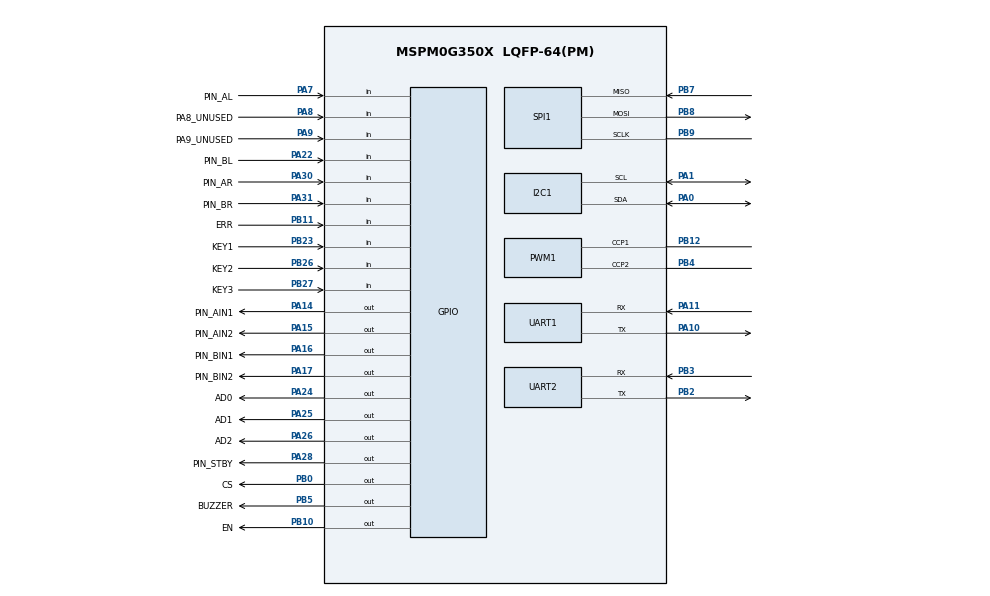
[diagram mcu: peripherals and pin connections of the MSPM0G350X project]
/**
 *
 * @cliArgs --device "MSPM0G350X" --part "Default" --package "LQFP-64(PM)" --product "mspm0_sdk@2.09.00.01"
 * @versions {"tool":"1.28.0+4696"}
 */

/**
 * Import the modules used in this configuration.
 */
const ADC12         = scripting.addModule("/ti/driverlib/ADC12", {}, false);
const ADC121        = ADC12.addInstance();
const GPIO          = scripting.addModule("/ti/driverlib/GPIO", {}, false);
const GPIO1         = GPIO.addInstance();
const GPIO2         = GPIO.addInstance();
const GPIO3         = GPIO.addInstance();
const GPIO4         = GPIO.addInstance();
const GPIO5         = GPIO.addInstance();
const GPIO6         = GPIO.addInstance();
const GPIO7         = GPIO.addInstance();
const GPIO8         = GPIO.addInstance();
const GPIO9         = GPIO.addInstance();
const GPIO10        = GPIO.addInstance();
const I2C           = scripting.addModule("/ti/driverlib/I2C", {}, false);
const I2C1          = I2C.addInstance();
const PWM           = scripting.addModule("/ti/driverlib/PWM", {}, false);
const PWM1          = PWM.addInstance();
const SPI           = scripting.addModule("/ti/driverlib/SPI", {}, false);
const SPI1          = SPI.addInstance();
const SYSCTL        = scripting.addModule("/ti/driverlib/SYSCTL");
const UART          = scripting.addModule("/ti/driverlib/UART", {}, false);
const UART1         = UART.addInstance();
const UART2         = UART.addInstance();
const WWDT          = scripting.addModule("/ti/driverlib/WWDT", {}, false);
const WWDT1         = WWDT.addInstance();
const ProjectConfig = scripting.addModule("/ti/project_config/ProjectConfig");

/**
 * Write custom configuration values to the imported modules.
 */
/* ADC0 serves the GRAY multiplexer output only. */
ADC121.$name                             = "ADC_GRAY";
ADC121.sampleTime0                       = "40 us";
ADC121.sampClkDiv                        = "DL_ADC12_CLOCK_DIVIDE_8";
ADC121.samplingOperationMode              = "sequence";
ADC121.endAdd                             = 0;
ADC121.enabledInterrupts                 = ["DL_ADC12_INTERRUPT_MEM0_RESULT_LOADED"];
ADC121.adcMem0_name                      = "GRAY_OUT";
ADC121.adcMem0chansel                    = "DL_ADC12_INPUT_CHAN_0";
ADC121.peripheral.$assign                = "ADC0";
ADC121.peripheral.adcPin0.$assign        = "PA27";
ADC121.adcPin0Config.hideOutputInversion = scripting.forceWrite(false);
ADC121.adcPin0Config.$name               = "GPIO_ADC_GRAY_OUT";

const Board = scripting.addModule("/ti/driverlib/Board", {}, false);

GPIO1.$name                         = "A";
GPIO1.associatedPins.create(2);
GPIO1.associatedPins[0].$name       = "PIN_AIN1";
GPIO1.associatedPins[0].pin.$assign = "PA14";
GPIO1.associatedPins[1].$name       = "PIN_AIN2";
GPIO1.associatedPins[1].pin.$assign = "PA15";

GPIO2.$name                         = "B";
GPIO2.associatedPins.create(2);
GPIO2.associatedPins[0].$name       = "PIN_BIN1";
GPIO2.associatedPins[0].pin.$assign = "PA16";
GPIO2.associatedPins[1].$name       = "PIN_BIN2";
GPIO2.associatedPins[1].pin.$assign = "PA17";

GPIO3.$name                         = "STBY";
GPIO3.associatedPins[0].$name       = "PIN_STBY";
GPIO3.associatedPins[0].pin.$assign = "PA28";

GPIO4.$name                         = "ENC_A";
GPIO4.associatedPins.create(2);
GPIO4.associatedPins[0].$name       = "PIN_AL";
GPIO4.associatedPins[0].direction   = "INPUT";
GPIO4.associatedPins[0].interruptEn = true;
GPIO4.associatedPins[0].polarity    = "RISE_FALL";
GPIO4.associatedPins[0].pin.$assign = "PA7";
GPIO4.associatedPins[1].$name       = "PIN_AR";
GPIO4.associatedPins[1].direction   = "INPUT";
GPIO4.associatedPins[1].interruptEn = true;
GPIO4.associatedPins[1].polarity    = "RISE_FALL";
GPIO4.associatedPins[1].pin.$assign = "PA30";

GPIO5.$name                         = "ENC_B";
GPIO5.associatedPins.create(2);
GPIO5.associatedPins[0].$name       = "PIN_BL";
GPIO5.associatedPins[0].direction   = "INPUT";
GPIO5.associatedPins[0].pin.$assign = "PA22";
GPIO5.associatedPins[1].$name       = "PIN_BR";
GPIO5.associatedPins[1].direction   = "INPUT";
GPIO5.associatedPins[1].polarity    = "RISE_FALL";
GPIO5.associatedPins[1].pin.$assign = "PA31";

GPIO6.$name                         = "GPIO_GRAY";
GPIO6.associatedPins.create(5);
GPIO6.associatedPins[0].$name       = "AD0";
GPIO6.associatedPins[0].pin.$assign = "PA24";
GPIO6.associatedPins[1].$name       = "AD1";
GPIO6.associatedPins[1].pin.$assign = "PA25";
GPIO6.associatedPins[2].$name       = "AD2";
GPIO6.associatedPins[2].pin.$assign = "PA26";
GPIO6.associatedPins[3].$name       = "ERR";
GPIO6.associatedPins[3].direction   = "INPUT";
GPIO6.associatedPins[3].pin.$assign = "PB11";
GPIO6.associatedPins[4].$name       = "EN";
GPIO6.associatedPins[4].pin.$assign = "PB10";

GPIO7.$name                          = "GPIO_IMU";
GPIO7.associatedPins[0].$name        = "CS";
GPIO7.associatedPins[0].initialValue = "SET";
GPIO7.associatedPins[0].pin.$assign  = "PB0";

GPIO8.$name                              = "GPIO_KEYS";
GPIO8.associatedPins.create(3);
GPIO8.associatedPins[0].$name            = "KEY1";
GPIO8.associatedPins[0].direction        = "INPUT";
GPIO8.associatedPins[0].internalResistor = "PULL_UP";
GPIO8.associatedPins[0].pin.$assign      = "PB23";
GPIO8.associatedPins[1].$name            = "KEY2";
GPIO8.associatedPins[1].direction        = "INPUT";
GPIO8.associatedPins[1].internalResistor = "PULL_UP";
GPIO8.associatedPins[1].pin.$assign      = "PB26";
GPIO8.associatedPins[2].$name            = "KEY3";
GPIO8.associatedPins[2].direction        = "INPUT";
GPIO8.associatedPins[2].internalResistor = "PULL_UP";
GPIO8.associatedPins[2].pin.$assign      = "PB27";

GPIO9.$name                         = "GPIO_BUZZER";
GPIO9.associatedPins[0].$name       = "BUZZER";
GPIO9.associatedPins[0].pin.$assign = "PB5";

GPIO10.$name                         = "GPIO_RESERVED";
GPIO10.associatedPins.create(2);
GPIO10.associatedPins[0].$name       = "PA8_UNUSED";
GPIO10.associatedPins[0].direction   = "INPUT";
GPIO10.associatedPins[0].pin.$assign = "PA8";
GPIO10.associatedPins[1].$name       = "PA9_UNUSED";
GPIO10.associatedPins[1].direction   = "INPUT";
GPIO10.associatedPins[1].pin.$assign = "PA9";

I2C1.$name                             = "I2C_OLED";
I2C1.basicEnableController             = true;
I2C1.basicControllerStandardBusSpeed   = "Fast";
I2C1.peripheral.$assign                = "I2C0";
I2C1.peripheral.sdaPin.$assign         = "PA0";
I2C1.peripheral.sclPin.$assign         = "PA1";
I2C1.sdaPinConfig.hideOutputInversion  = scripting.forceWrite(false);
I2C1.sdaPinConfig.onlyInternalResistor = scripting.forceWrite(false);
I2C1.sdaPinConfig.passedPeripheralType = scripting.forceWrite("Digital");
I2C1.sdaPinConfig.$name                = "GPIO_I2C_OLED_SDA";
I2C1.sclPinConfig.hideOutputInversion  = scripting.forceWrite(false);
I2C1.sclPinConfig.onlyInternalResistor = scripting.forceWrite(false);
I2C1.sclPinConfig.passedPeripheralType = scripting.forceWrite("Digital");
I2C1.sclPinConfig.$name                = "GPIO_I2C_OLED_SCL";

PWM1.$name                              = "PWM_TB1";
PWM1.timerCount                         = 1600;
PWM1.ccIndex                            = [1,2];
PWM1.ccp1PinConfig.direction            = scripting.forceWrite("OUTPUT");
PWM1.ccp1PinConfig.hideOutputInversion  = scripting.forceWrite(false);
PWM1.ccp1PinConfig.onlyInternalResistor = scripting.forceWrite(false);
PWM1.ccp1PinConfig.passedPeripheralType = scripting.forceWrite("Digital");
PWM1.ccp1PinConfig.$name                = "ti_driverlib_gpio_GPIOPinGeneric1";
PWM1.peripheral.$assign                 = "TIMA0";
PWM1.peripheral.ccp1Pin.$assign         = "PB12";
PWM1.peripheral.ccp2Pin.$assign         = "PB4";
PWM1.PWM_CHANNEL_2.$name                = "ti_driverlib_pwm_PWMTimerCC1";
PWM1.ccp2PinConfig.$name                = "ti_driverlib_gpio_GPIOPinGeneric0";
PWM1.PWM_CHANNEL_1.$name                = "ti_driverlib_pwm_PWMTimerCC0";

SPI1.$name                              = "SPI_IMU";
SPI1.targetBitRate                      = 4000000;
SPI1.frameFormat                        = "MOTO3";
SPI1.chipSelect                         = [];
SPI1.sclkPinConfig.direction            = scripting.forceWrite("OUTPUT");
SPI1.sclkPinConfig.onlyInternalResistor = scripting.forceWrite(false);
SPI1.sclkPinConfig.passedPeripheralType = scripting.forceWrite("Digital");
SPI1.sclkPinConfig.$name                = "GPIO_SPI_IMU_SCLK";
SPI1.mosiPinConfig.direction            = scripting.forceWrite("OUTPUT");
SPI1.mosiPinConfig.hideOutputInversion  = scripting.forceWrite(false);
SPI1.mosiPinConfig.onlyInternalResistor = scripting.forceWrite(false);
SPI1.mosiPinConfig.passedPeripheralType = scripting.forceWrite("Digital");
SPI1.mosiPinConfig.$name                = "GPIO_SPI_IMU_MOSI";
SPI1.misoPinConfig.onlyInternalResistor = scripting.forceWrite(false);
SPI1.misoPinConfig.passedPeripheralType = scripting.forceWrite("Digital");
SPI1.misoPinConfig.$name                = "GPIO_SPI_IMU_MISO";
SPI1.peripheral.$assign                 = "SPI1";
SPI1.peripheral.sclkPin.$assign         = "PB9";
SPI1.peripheral.mosiPin.$assign         = "PB8";
SPI1.peripheral.misoPin.$assign         = "PB7";

SYSCTL.forceDefaultClkConfig = true;
SYSCTL.clockTreeEn           = true;

UART1.$name                            = "UART_DEBUG";
UART1.targetBaudRate                   = 115200;
UART1.peripheral.rxPin.$assign         = "PA11";
UART1.peripheral.txPin.$assign         = "PA10";
UART1.txPinConfig.direction            = scripting.forceWrite("OUTPUT");
UART1.txPinConfig.hideOutputInversion  = scripting.forceWrite(false);
UART1.txPinConfig.onlyInternalResistor = scripting.forceWrite(false);
UART1.txPinConfig.passedPeripheralType = scripting.forceWrite("Digital");
UART1.txPinConfig.$name                = "ti_driverlib_gpio_GPIOPinGeneric2";
UART1.rxPinConfig.hideOutputInversion  = scripting.forceWrite(false);
UART1.rxPinConfig.onlyInternalResistor = scripting.forceWrite(false);
UART1.rxPinConfig.passedPeripheralType = scripting.forceWrite("Digital");
UART1.rxPinConfig.$name                = "ti_driverlib_gpio_GPIOPinGeneric3";

UART2.$name                            = "UART_VOFA";
UART2.targetBaudRate                   = 115200;
UART2.enabledInterrupts                = ["RX"];
UART2.enableFIFO                       = true;
UART2.rxFifoThreshold                  = "DL_UART_RX_FIFO_LEVEL_ONE_ENTRY";
UART2.txFifoThreshold                  = "DL_UART_TX_FIFO_LEVEL_1_2_EMPTY";
UART2.peripheral.$assign               = "UART3";
UART2.peripheral.rxPin.$assign         = "PB3";
UART2.peripheral.txPin.$assign         = "PB2";
UART2.txPinConfig.direction            = scripting.forceWrite("OUTPUT");
UART2.txPinConfig.hideOutputInversion  = scripting.forceWrite(false);
UART2.txPinConfig.onlyInternalResistor = scripting.forceWrite(false);
UART2.txPinConfig.passedPeripheralType = scripting.forceWrite("Digital");
UART2.txPinConfig.$name                = "ti_driverlib_gpio_GPIOPinGeneric4";
UART2.rxPinConfig.hideOutputInversion  = scripting.forceWrite(false);
UART2.rxPinConfig.onlyInternalResistor = scripting.forceWrite(false);
UART2.rxPinConfig.passedPeripheralType = scripting.forceWrite("Digital");
UART2.rxPinConfig.$name                = "ti_driverlib_gpio_GPIOPinGeneric5";

WWDT1.$name               = "WWDT0";
WWDT1.clockDivider        = "4";
WWDT1.wwdtMode            = "WATCHDOG";
WWDT1.periodCount         = "15";
WWDT1.activeWindow        = "0";
WWDT1.window0ClosedPeriod = "0";
WWDT1.window1ClosedPeriod = "0";
WWDT1.sleepMode           = true;
WWDT1.enabledInterrupts   = false;
WWDT1.peripheral.$assign  = "WWDT0";

ProjectConfig.deviceSpin = "MSPM0G3507";

/**
 * Pinmux solution for unlocked pins/peripherals. This ensures that minor changes to the automatic solver in a future
 * version of the tool will not impact the pinmux you originally saw.  These lines can be completely deleted in order to
 * re-solve from scratch.
 */
Board.peripheral.$suggestSolution          = "DEBUGSS";
Board.peripheral.swclkPin.$suggestSolution = "PA20";
Board.peripheral.swdioPin.$suggestSolution = "PA19";
UART1.peripheral.$suggestSolution          = "UART0";
